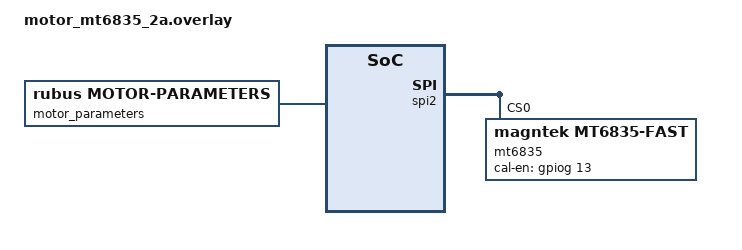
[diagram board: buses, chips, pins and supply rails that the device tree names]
/*
 * Motor profile overlay for integrated MT6835 encoder setup.
 *
 * Usage:
 *   west build ... -- \
 *     -DDTC_OVERLAY_FILE="app/boards/smartstepper_v2.overlay;app/configs/motor_mt6835_2a.overlay"
 *
 * Notes:
 * - This overrides only motor/sensor profile parameters.
 * - Keep board pin/peripheral wiring in the board overlay.
 */

/ {
	aliases {
		/* Use integrated MT6835 fast frontend for control-loop encoder input. */
		encoder1 = &mt6835;
	};

	user_parameters: user_parameters {
		compatible = "rubus,user-parameters";
		nominal_voltage-mv = <24000>;
		pwm-frequency-hz = <20000>;
		control-loop-frequency-hz = <20000>;
		current-loop-bandwidth-hz = <150>;
		current-command-ramp-ms = <100>;
		chopper-slot-count = <8>;
		offset-pole-hz = <300>;
		/* MT6835 positive direction convention is inverted from controller positive motion. */
		encoder-direction-sign = <(-1)>;
		align-current-ma = <200>;
		align-duration-ms = <100>;
		brake-current-ma = <1500>;
		max-modulation-index-mpu = <950>;
		roverl-est-current-ma = <300>;
		roverl-est-freq-hz = <250>;
		roverl-est-settling-ms = <50>;
		roverl-est-duration-ms = <5000>;
		commission-electrical-rs-current-ma = <300>;
		commission-electrical-current-limit-ma = <300>;
		commission-electrical-demod-pulse-mv = <500>;
		commission-electrical-max-pulse-mv = <500>;
		rls-excitation-current-ma = <100>;
		/* This 50 pole-pair motor is voltage-speed limited on a ~24 V bus. */
		velocity-max-hz = <5>;
		velocity-max-accel-hz-per-s = <20>;
		velocity-initial-hz = <0>;
		commission-standard-min-auto-iq-ma = <250>;
		commission-validate-current-default-iq-ma = <80>;
	};

	motor_parameters: motor_parameters {
		compatible = "rubus,motor-parameters";
		/* Boot fallback updated from on-hardware electrical commissioning. */
		inductance-d-uh = <2903>;
		inductance-q-uh = <2903>;
		resistance-mohms = <2253>;
		max-current-ma = <1500>;
		/*
		 * These are placeholders. Set from measured motor:
		 * - pole-pairs
		 * - max-speed-hz
		 */
		pole-pairs = <50>;
		/* Boot/fallback only; commissioning estimates runtime inertia. */
		inertia-mgcm2 = <57000>;
		max-speed-hz = <5>;
	};

	fault_detection: fault_detection {
		compatible = "rubus,fault-detection";
		encoder-fault-threshold = <100>;
		/* 120% of 1.5 A current limit. */
		overcurrent-threshold-ma = <1800>;
	};
};

&spi2 {
	compatible = "rubus,stm32-rt-spi";
	status = "okay";
	spi-clock-frequency = <DT_FREQ_M(12)>;
	max-frame-len = <6>;
	cs-mode = "hardware";
	spi-cpol;
	spi-cpha;
	fifo-enable;

	mt6835: mt6835@0 {
		compatible = "magntek,mt6835-fast";
		reg = <0>;
		pipeline-delay-samples = <0>;
		cal-en-gpios = <&gpiog 13 GPIO_ACTIVE_HIGH>;
		status = "okay";
	};
};
